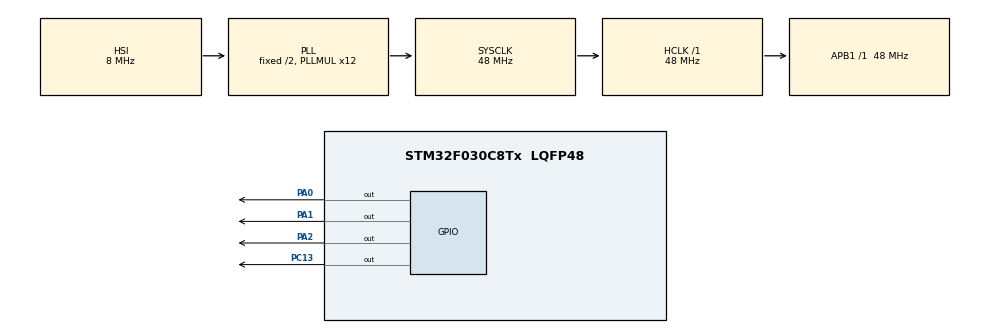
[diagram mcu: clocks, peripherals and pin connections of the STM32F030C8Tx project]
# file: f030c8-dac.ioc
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Mcu.Family=STM32F0
Mcu.Name=STM32F030C8Tx
Mcu.Package=LQFP48
NVIC.TIM1_BRK_UP_TRG_COM_IRQn=true\:0\:0\:false\:false\:true\:true\:true
PA0.Signal=GPIO_Output
PA1.Signal=GPIO_Output
PA2.Signal=GPIO_Output
PC13.Signal=GPIO_Output
ProjectManager.HeapSize=0x200
ProjectManager.StackSize=0x400
ProjectManager.TargetToolchain=Makefile
RCC.AHBFreq_Value=48000000
RCC.APB1Freq_Value=48000000
RCC.APB1TimFreq_Value=48000000
RCC.HCLKFreq_Value=48000000
RCC.PLLMUL=RCC_PLL_MUL12
RCC.SYSCLKFreq_VALUE=48000000
RCC.SYSCLKSource=RCC_SYSCLKSOURCE_PLLCLK
TIM1.AutoReloadPreload=TIM_AUTORELOAD_PRELOAD_ENABLE
TIM1.ClockDivision=TIM_CLOCKDIVISION_DIV2
TIM1.Period=1234
VP_TIM1_VS_ClockSourceINT.Mode=Internal
board=custom

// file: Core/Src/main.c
/* USER CODE BEGIN Header */
/**
  ******************************************************************************
  * @file           : main.c
  * @brief          : Main program body
  ******************************************************************************
  * @attention
  *
  * <h2><center>&copy; Copyright (c) 2022 STMicroelectronics.
  * All rights reserved.</center></h2>
  *
  * This software component is licensed by ST under BSD 3-Clause license,
  * the "License"; You may not use this file except in compliance with the
  * License. You may obtain a copy of the License at:
  *                        opensource.org/licenses/BSD-3-Clause
  *
  ******************************************************************************
  */
/* USER CODE END Header */
#include "main.h"
#include "pt8211.h"
#include "math.h"

// PCM buffers
#define PCM_BUF_SIZE 128

volatile int pLeft[PCM_BUF_SIZE], pRight[PCM_BUF_SIZE];

TIM_HandleTypeDef htim1;

void SystemClock_Config(void);
static void MX_GPIO_Init(void);
static void MX_TIM1_Init(void);

int main(void)
{
  /* USER CODE BEGIN 1 */
  int i, j;
  int wSize = PCM_BUF_SIZE;

  /* USER CODE END 1 */

  /* MCU Configuration--------------------------------------------------------*/

  /* Reset of all peripherals, Initializes the Flash interface and the Systick. */
  HAL_Init();

  /* Configure the system clock */
  SystemClock_Config();

  /* Initialize all configured peripherals */
  MX_GPIO_Init();
  MX_TIM1_Init();
  /* USER CODE BEGIN 2 */
  pt8211Init();

  for(i=0; i<wSize; i++){
    pLeft[i] = sin(i*2*M_PI/wSize)*65535/2;
    pRight[i] = 65535*i/wSize;
  }

  while(1) {
    for(j=0; j<65535; j++){
      for(i=0; i<wSize; i++){
        pt8211StereoOut(pLeft[i], pRight[i]); // 11us per sample
        //pt8211MonoOut(pLeft[i]); // 6us per sample (up 18%)
      }
    }
  }
}

void SystemClock_Config(void)
{
  RCC_OscInitTypeDef RCC_OscInitStruct = {0};
  RCC_ClkInitTypeDef RCC_ClkInitStruct = {0};

  /** Initializes the RCC Oscillators according to the specified parameters
  * in the RCC_OscInitTypeDef structure.
  */
  RCC_OscInitStruct.OscillatorType = RCC_OSCILLATORTYPE_HSI;
  RCC_OscInitStruct.HSIState = RCC_HSI_ON;
  RCC_OscInitStruct.HSICalibrationValue = RCC_HSICALIBRATION_DEFAULT;
  RCC_OscInitStruct.PLL.PLLState = RCC_PLL_ON;
  RCC_OscInitStruct.PLL.PLLSource = RCC_PLLSOURCE_HSI;
  RCC_OscInitStruct.PLL.PLLMUL = RCC_PLL_MUL12;
  RCC_OscInitStruct.PLL.PREDIV = RCC_PREDIV_DIV1;
  if (HAL_RCC_OscConfig(&RCC_OscInitStruct) != HAL_OK)
  {
    Error_Handler();
  }
  /** Initializes the CPU, AHB and APB buses clocks
  */
  RCC_ClkInitStruct.ClockType = RCC_CLOCKTYPE_HCLK|RCC_CLOCKTYPE_SYSCLK
                              |RCC_CLOCKTYPE_PCLK1;
  RCC_ClkInitStruct.SYSCLKSource = RCC_SYSCLKSOURCE_PLLCLK;
  RCC_ClkInitStruct.AHBCLKDivider = RCC_SYSCLK_DIV1;
  RCC_ClkInitStruct.APB1CLKDivider = RCC_HCLK_DIV1;

  if (HAL_RCC_ClockConfig(&RCC_ClkInitStruct, FLASH_LATENCY_1) != HAL_OK)
  {
    Error_Handler();
  }
}

static void MX_TIM1_Init(void)
{

  TIM_ClockConfigTypeDef sClockSourceConfig = {0};
  TIM_MasterConfigTypeDef sMasterConfig = {0};

  htim1.Instance = TIM1;
  htim1.Init.Prescaler = 0;
  htim1.Init.CounterMode = TIM_COUNTERMODE_UP;
  htim1.Init.Period = 1234;
  htim1.Init.ClockDivision = TIM_CLOCKDIVISION_DIV2;
  htim1.Init.RepetitionCounter = 0;
  htim1.Init.AutoReloadPreload = TIM_AUTORELOAD_PRELOAD_ENABLE;
  if (HAL_TIM_Base_Init(&htim1) != HAL_OK)
  {
    Error_Handler();
  }
  sClockSourceConfig.ClockSource = TIM_CLOCKSOURCE_INTERNAL;
  if (HAL_TIM_ConfigClockSource(&htim1, &sClockSourceConfig) != HAL_OK)
  {
    Error_Handler();
  }
  sMasterConfig.MasterOutputTrigger = TIM_TRGO_RESET;
  sMasterConfig.MasterSlaveMode = TIM_MASTERSLAVEMODE_DISABLE;
  if (HAL_TIMEx_MasterConfigSynchronization(&htim1, &sMasterConfig) != HAL_OK)
  {
    Error_Handler();
  }

}

static void MX_GPIO_Init(void)
{
  GPIO_InitTypeDef GPIO_InitStruct = {0};

  /* GPIO Ports Clock Enable */
  __HAL_RCC_GPIOC_CLK_ENABLE();

  /*Configure GPIO pin Output Level */
  HAL_GPIO_WritePin(GPIOC, GPIO_PIN_13, GPIO_PIN_RESET);

  /*Configure GPIO pin : PC13 */
  GPIO_InitStruct.Pin = GPIO_PIN_13;
  GPIO_InitStruct.Mode = GPIO_MODE_OUTPUT_PP;
  GPIO_InitStruct.Pull = GPIO_NOPULL;
  GPIO_InitStruct.Speed = GPIO_SPEED_FREQ_LOW;
  HAL_GPIO_Init(GPIOC, &GPIO_InitStruct);

}

void Error_Handler(void)
{
  __disable_irq();
  while (1)
  {
  }
}

/************************ (C) COPYRIGHT STMicroelectronics *****END OF FILE****/
